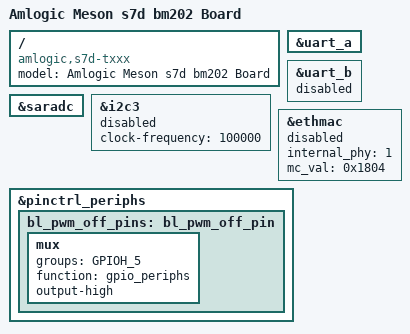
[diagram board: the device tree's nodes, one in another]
// SPDX-License-Identifier: (GPL-2.0+ OR MIT)
/*
 * Copyright (c) 2019 Amlogic, Inc. All rights reserved.
 */

/dts-v1/;

#include "amlogic/meson-s7d-bm202.dtsi"
#include "amlogic/meson-s7d_bm202-panel.dtsi"

/ {
	compatible =  "amlogic,s7d-txxx", "amlogic,meson-s7d";
	model = "Amlogic Meson s7d bm202 Board";
};

/* This UART is brought out to the DB9 connector */
&uart_a {
	status = "okay";
};

&uart_b {
	status = "disabled";
};

&saradc {
	status = "okay";
};

/* demo for i2c user */
&i2c3 {
	status= "disabled";
	clock-frequency = <100000>;
	/* pinctrl-names = "default";*/
	/* pinctrl-0 = <&i2c3_master_pins2>;*/
};

&ethmac {
	status = "disabled";
	internal_phy = <1>;
	mc_val = <0x1804>;
	/*mc_val = <0x1621>;*/
};

&pinctrl_periphs {
	bl_pwm_off_pins:bl_pwm_off_pin {
		mux {
			groups = "GPIOH_5";
			function = "gpio_periphs";
			output-high;
		};
	};
}; /* end of pinctrl_periphs */
